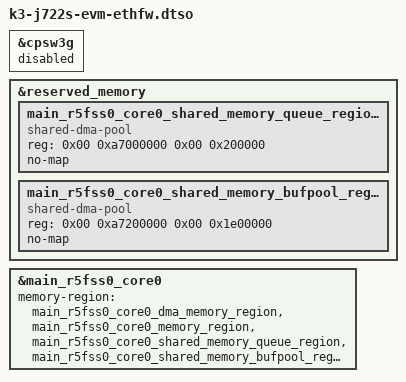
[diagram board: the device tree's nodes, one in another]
// SPDX-License-Identifier: GPL-2.0-only OR MIT
/**
 * DT Overlay for CPSW3G functionality with Ethernet Switch Firmware (EthFw)
 * and CPSW Proxy Client driver.
 *
 * Copyright (C) 2026 Texas Instruments Incorporated - https://www.ti.com/
 */

/dts-v1/;
/plugin/;

/* Mark CPSW3G reserved for EthFw. */
&cpsw3g {
	status = "reserved";
};

/* Reserve shared memory for inter-core network communication. */
&reserved_memory {
	#address-cells = <2>;
	#size-cells = <2>;

	main_r5fss0_core0_shared_memory_queue_region:r5f-virtual-eth-queues@a7000000 {
		compatible = "shared-dma-pool";
		reg = <0x00 0xa7000000 0x00 0x200000>;
		no-map;
	};

	main_r5fss0_core0_shared_memory_bufpool_region:r5f-virtual-eth-buffers@a7200000 {
		compatible = "shared-dma-pool";
		reg = <0x00 0xa7200000 0x00 0x1e00000>;
		no-map;
	};
};

&main_r5fss0_core0 {
	memory-region = <&main_r5fss0_core0_dma_memory_region>,
			<&main_r5fss0_core0_memory_region>,
			<&main_r5fss0_core0_shared_memory_queue_region>,
			<&main_r5fss0_core0_shared_memory_bufpool_region>;
};
